# S32R372 register map
Vendor: Freescale Semiconductor, Inc.; Series: Qorivva; File version: 1.6
Registers are 32-bit, read-write, reset 0x0 unless marked. A register's access mark holds for its fields unless they carry their own. Offsets are from the block's base; [hi:lo] are bit positions; {n}, {i} and the like mark numbered series.

## AFE
Base 0xFBF0C000; register names take the prefix AFE_
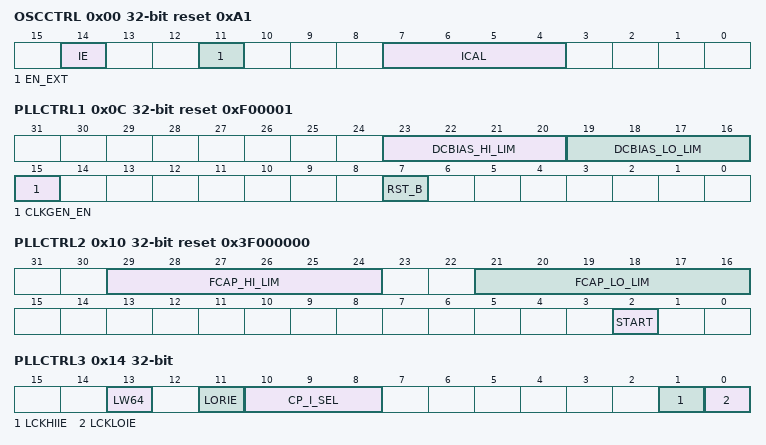
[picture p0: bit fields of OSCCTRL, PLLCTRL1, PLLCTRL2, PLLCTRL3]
0x00 OSCCTRL reset 0xA1 — Oscillator Control Register
  [14] IE — Oscillator interrupt enable
    0=Oscillator interrupt disabled; 1=Oscillator interrupt enabled
  [11] EN_EXT — Crystal oscillator bypass control
    0=Crystal mode, no bypass; 1=40 MHz external clock enabled. Do not set this bit when the crystal oscillator is operating.
  [7:4] ICAL — Variable current select bits. This field controls the oscillator's and buffer's variable currents.
    0bxx00=Oscillator bias 10uA; 0bxx01=Oscillator bias 15uA; 0bxx10=Oscillator bias 20uA; 0bxx11=Oscillator bias 25uA; 0b00xx=Buffer bias 50uA; 0b01xx=Buffer bias 100uA; 0b10xx=Buffer bias 150uA; 0b11xx=Buffer bias 200uA
0x04 OSCSTS ro — Oscillator Status Register
  [0] STS — Oscillator status
    0=Oscillator has not completed transition count; 1=Oscillator has completed transition count
0x08 OSCDLY reset 0x80 — Oscillator Delay Register
  [7:0] EOCV — End of count value
0x0C PLLCTRL1 reset 0xF00001 — SDPLL Control Register 1
  [23:20] DCBIAS_HI_LIM — This field is used to limit the high (maximum) value of the DC bias bus used during the SDPLL calibration
  [19:16] DCBIAS_LO_LIM — This field is used to limit the low (minimum) value of the DC bias bus used during the SDPLL calibration
  [15] CLKGEN_EN — Clock generation enable
    0=Disable clock generation; 1=Enable generation of 160 MHz and 80 MHz clocks
  [7] RST_B — Lock reset. This bit resets the SDPLL lock detect and test circuitry.
    0=Reset the SDPLL lock detect and test circuits; 1=Normal operation
0x10 PLLCTRL2 reset 0x3F000000 — SDPLL Control Register 2
  [29:24] FCAP_HI_LIM — This field is used to limit the high (maximum) value of the FCAP bus used during the SDPLL calibration
  [21:16] FCAP_LO_LIM — This field is used to limit the low (minimum) value of the FCAP bus used during the SDPLL calibration
  [2] START — Start DCbias and Fcap calibration in SDPLL
    0=Stop DCbias and/or Fcap calibration in SDPLL; 1=Start DCbias and/or Fcap calibration in SDPLL
0x14 PLLCTRL3 — SDPLL Control Register 3
  [13] LW64 — SDPLL calibration wait time adjustment.
    0=Default wait time of 256 reference clock cycles is used; 1=A wait time of 64 reference clock cycles is used
  [11] LORIE — Loss of reference interrupt enable
    0=SDPLL loss of reference interrupt disabled; 1=SDPLL loss of reference interrupt enabled
  [10:8] CP_I_SEL — Charge pump current select bits.
    4=Recommended value
  [1] LCKHIIE — SDPLL lock high interrupt enable
    0=SDLL interrupt disabled. Interrupt will not assert when SDPLL locks.; 1=SDPLL interrupt enabled. Interrupt will assert when SDPLL locks.
  [0] LCKLOIE — SDPLL lock loss interrupt enable
    0=SDPLL lock loss interrupt disabled. Interrupt will not assert when SDPLL loses lock.; 1=SDPLL lock loss interrupt enabled. Interrupt will assert when SDPLL loses lock.
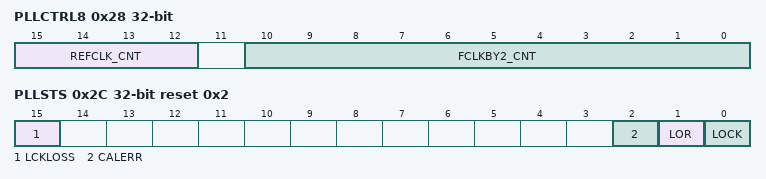
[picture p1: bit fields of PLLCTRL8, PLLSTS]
0x28 PLLCTRL8 — SDPLL Control Register 8
  [15:12] REFCLK_CNT — Programmable reference clock count
  [10:0] FCLKBY2_CNT — Programmable Fvco/2 clock count
0x2C PLLSTS reset 0x2 — SDPLL Status Register
  [15] LCKLOSS — SDPLL loss of lock indicator
    0=SDPLL has not fallen out of lock; 1=SDPLL has fallen out of lock
  [2] CALERR ro — SDPLL calibration error.
    0=SDPLL calibration successful; 1=An error occurred during SDPLL calibration
  [1] LOR ro — SDPLL loss of reference
    0=SDPLL reference clock is toggling; 1=SDPLL reference clock is not toggling
  [0] LOCK ro — SDPLL lock indicator
    0=SDPLL has not locked; 1=SDPLL has calibrated and locked
0x54 VRFCTRL1 ro — VREF Control Register 1
0x5C LVDSTS ro reset 0x2000000 — Low Voltage Detect Status Register
  [25] BGOK — 1.2V Vref is up and available.
    0=1.2V Vref is not present; 1=1.2V Vref is present
{0x5C+4i} VRGCTRL{i} ro (i=5..8) — VREG{i} Control Register
